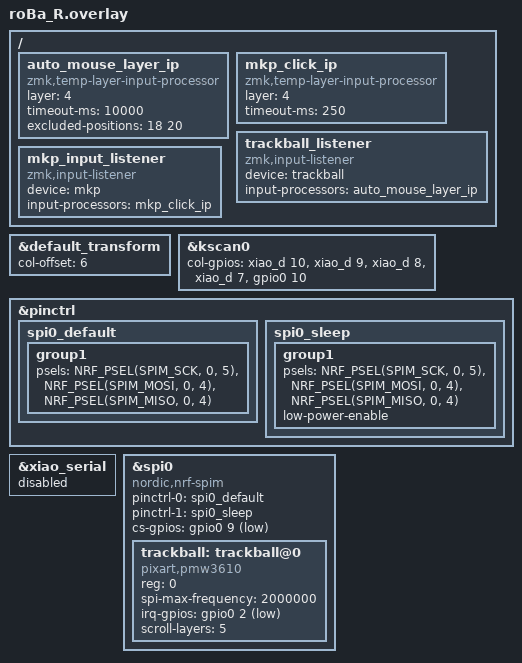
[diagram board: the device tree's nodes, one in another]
#include "roBa.dtsi"
#include <input/processors.dtsi>

&default_transform {
    col-offset = <6>;
};

&kscan0 {
    col-gpios
        = <&xiao_d 10 GPIO_ACTIVE_HIGH>
        , <&xiao_d 9 GPIO_ACTIVE_HIGH>
        , <&xiao_d 8 GPIO_ACTIVE_HIGH>
        , <&xiao_d 7 GPIO_ACTIVE_HIGH>
        , <&gpio0 10 GPIO_ACTIVE_HIGH>
        ;
};

/ {
    /* movement -> layer 4 for 10s, non-mouse keys exit immediately
       J=18, L=20 only are excluded (mouse buttons) */
    auto_mouse_layer_ip: auto_mouse_layer_ip {
        compatible = "zmk,temp-layer-input-processor";
        layer = <4>;
        timeout-ms = <10000>;
        excluded-positions = <18 20>;
    };

    /* click -> layer 4 for 250ms */
    mkp_click_ip: mkp_click_ip {
        compatible = "zmk,temp-layer-input-processor";
        layer = <4>;
        timeout-ms = <250>;
    };

    trackball_listener: trackball_listener {
        compatible = "zmk,input-listener";
        device = <&trackball>;
        input-processors = <&auto_mouse_layer_ip>;
    };

    mkp_input_listener {
        compatible = "zmk,input-listener";
        device = <&mkp>;
        input-processors = <&mkp_click_ip>;
    };
};

&pinctrl {
    spi0_default: spi0_default {
        group1 {
            psels = <NRF_PSEL(SPIM_SCK, 0, 5)>,
                    <NRF_PSEL(SPIM_MOSI, 0, 4)>,
                    <NRF_PSEL(SPIM_MISO, 0, 4)>;
        };
    };

    spi0_sleep: spi0_sleep {
        group1 {
            psels = <NRF_PSEL(SPIM_SCK, 0, 5)>,
                    <NRF_PSEL(SPIM_MOSI, 0, 4)>,
                    <NRF_PSEL(SPIM_MISO, 0, 4)>;
            low-power-enable;
        };
    };
};

&xiao_serial { status = "disabled"; };

&spi0 {
    status = "okay";
    compatible = "nordic,nrf-spim";
    pinctrl-0 = <&spi0_default>;
    pinctrl-1 = <&spi0_sleep>;
    pinctrl-names = "default", "sleep";
    cs-gpios = <&gpio0 9 GPIO_ACTIVE_LOW>;

    trackball: trackball@0 {
        status = "okay";
        compatible = "pixart,pmw3610";
        reg = <0>;
        spi-max-frequency = <2000000>;
        irq-gpios = <&gpio0 2 (GPIO_ACTIVE_LOW | GPIO_PULL_UP)>;
        scroll-layers = <5>;
    };
};
